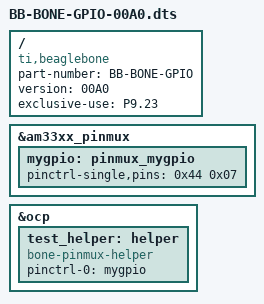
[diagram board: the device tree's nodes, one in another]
    /*  
    * GPIO cape dts file BB-BONE-GPIO-00A0.dts  
    */  
    /dts-v1/;  
    /plugin/;  
      
    / {  
      compatible = "ti,beaglebone", "ti,beaglebone-black";  
      
      /* identification */  
      part-number = "BB-BONE-GPIO";  
      version = "00A0";  
      
      exclusive-use =  
        "P9.23";  
      
      fragment@0 {  
        target = <&am33xx_pinmux>;  
        __overlay__ {  
          mygpio: pinmux_mygpio{  
            pinctrl-single,pins = <  
              0x44 0x07 // GPIO1_17, P9.23
              >;  
          };  
        };  
      };  
      
      fragment@1 {  
        target = <&ocp>;  
        __overlay__ {  
          test_helper: helper {  
            compatible = "bone-pinmux-helper";  
            pinctrl-names = "default";  
            pinctrl-0 = <&mygpio>;  
            status = "okay";  
          };  
        };  
      };  
      
    };  
